# WB32F10x register map
File version: 1.2
CPU: CM3 r2p0, little endian, MPU, no FPU, 4 interrupt priority bits
Registers are 32-bit, read-write, reset 0x0 unless marked. A register's access mark holds for its fields unless they carry their own. Offsets are from the block's base; [hi:lo] are bit positions; {n}, {i} and the like mark numbered series; 'fields as' and 'values as' point back to an identical list.

## RTC — Real time clock controller
Base 0x40015800
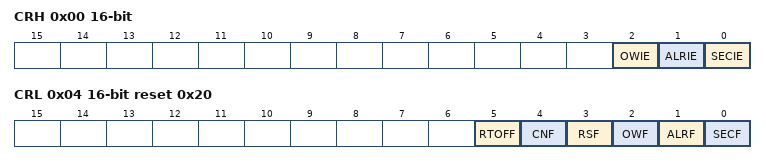
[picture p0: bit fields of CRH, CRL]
0x00 CRH 16-bit — Control high register
  [2] OWIE — Overflow interrupt enable
  [1] ALRIE — Alarm interrupt enable
  [0] SECIE — Second interrupt enable
0x04 CRL 16-bit reset 0x20 — Control low register
  [5] RTOFF — RTC operation turn-off flag
  [4] CNF — Configuration flag
  [3] RSF — Register synchronization flag
  [2] OWF — Overflow flag
  [1] ALRF — Alarm flag
  [0] SECF — Second flag
0x08 PRLH 16-bit wo — Prescaler high register
  [3:0] PRL — Prescaler high bits
0x0C PRLL 16-bit wo reset 0x8000 — Prescaler low register
  [15:0] PRL — Prescaler low bits
0x0C PRL ro (alternate view of PRLL) — Prescaler load register
  [31:0] PRL — Prescaler load
0x10 DIVH 16-bit ro — RTC clock divider high register
  [3:0] DIV — RTC clock divider high
0x14 DIVL 16-bit ro reset 0x8000 — RTC clock divider low register
  [15:0] DIV — RTC clock divider low
0x14 DIV ro (alternate view of DIVL) — RTC clock divider register
  [31:0] DIV — RTC clock divider
0x18 CNTH 16-bit — RTC counter high register
  [15:0] CNT — RTC counter high
0x1C CNTL 16-bit — RTC counter low register
  [15:0] CNT — RTC counter low
0x1C CNT ro (alternate view of CNTL) — RTC counter register
0x20 ALRH 16-bit wo reset 0xFFFF — RTC alarm high register
  [15:0] ALR — RTC alarm high
0x24 ALRL 16-bit wo reset 0xFFFF — RTC alarm low register
  [15:0] ALR — RTC alarm low
0x24 ALR ro reset 0xFFFFFFFF (alternate view of ALRL) — RTC alarm register

## WWDG — Window watchdog
Base 0x40009800
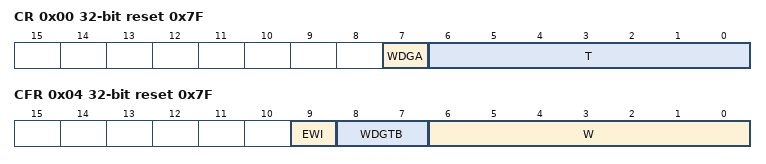
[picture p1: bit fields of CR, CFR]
0x00 CR reset 0x7F — Control register
  [7] WDGA — Window watchdog active bit
  [6:0] T — 7 bits counter
0x04 CFR reset 0x7F — Configuration register
  [9] EWI — Early wakeup interrupt
  [8:7] WDGTB — Window watchdog time base
  [6:0] W — 7 bits window value
0x08 SR — Status register
  [0] EWIF — Early wakeup interrupt flag

## IWDG — Independent watchdog
Base 0x40010800
0x00 KR wo — Key register
  [15:0] KEY — Key value
0x04 PR — Prescaler divider register
  [2:0] PR — Prescaler divider
0x08 RLR reset 0xFFF — Reload register
  [0] RL — Watchdog counter reload value
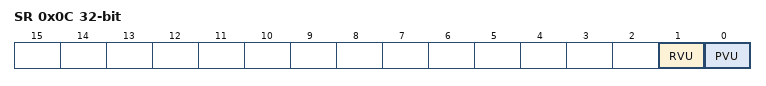
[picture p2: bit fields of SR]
0x0C SR ro — Status register
  [1] RVU — Watchdog counter reload value update
  [0] PVU — Watchdog prescaler value update

## DBGMCU — Debug MCU
Base 0xE0042000
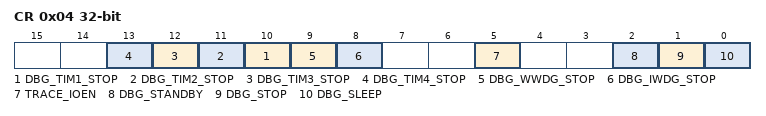
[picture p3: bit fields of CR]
0x04 CR — Control register
  [n+9] DBG_TIM{n}_STOP (n=1..4) — Timer {n} stop working in debug mode
  [9] DBG_WWDG_STOP — Window watchdog stop working in debug mode
  [8] DBG_IWDG_STOP — Independent watchdog stop working in debug mode
  [5] TRACE_IOEN — Trace IO enable
  [2] DBG_STANDBY — Debug standby mode
  [1] DBG_STOP — Debug stop mode
  [0] DBG_SLEEP — Debug sleep mode

## SFM — Special function macro
Base 0x40014C00
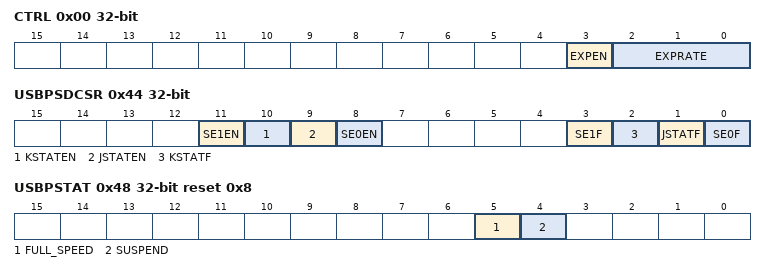
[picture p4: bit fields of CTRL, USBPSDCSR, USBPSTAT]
0x00 CTRL — Control register
  [3] EXPEN — Expand enable
  [2:0] EXPRATE — Expand rate
0x04 DATA
{0x8+4i} DOUTR{i} ro (i=0..7) — Data output register {i}
  [31:0] DOUT — Data output
0x44 USBPSDCSR — Usb port state detect control/status register
  [11] SE1EN — USB SE1 state detect enable
  [10] KSTATEN — USB K state detect enable
  [9] JSTATEN — USB J state detect enable
  [8] SE0EN — USB SE0 state detect enable
  [3] SE1F — USB switches to SE1 state from port state flag
  [2] KSTATF — USB switches to K state from port state flag
  [1] JSTATF — USB switches to J state from port state flag
  [0] SE0F — USB switches to SE0 state from port state flag
0x48 USBPSTAT ro reset 0x8 — Usb port state register
  [5] FULL_SPEED — Full speed state
  [4] SUSPEND — Suspend state

## CACHE — Cache controller
Base 0x40015400
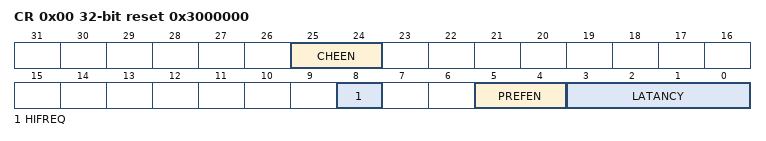
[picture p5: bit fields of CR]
0x00 CR reset 0x3000000 — Control register
  [25:24] CHEEN — Cache enable
  [8] HIFREQ — High frequency access assistance
  [5:4] PREFEN — Prefetch instruction enable
  [3:0] LATANCY — Flash memory access waiting latency

## FMC — Flash memory controller
Base 0x40017800
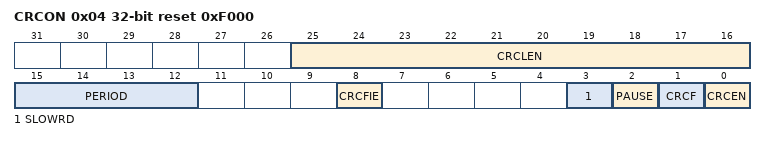
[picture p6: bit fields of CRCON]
0x04 CRCON reset 0xF000 — CRC control register
  [25:16] CRCLEN — CRC calculation length
  [15:12] PERIOD — Period to read flash while CRC calculation
  [8] CRCFIE — CRC calculation complete interrupt enable
  [3] SLOWRD — Control CRC calculation interval period
  [2] PAUSE — CRC pause
  [1] CRCF — CRC calculation complete flag
  [0] CRCEN — CRC enable
0x10 ADDR — Address register
  [31:0] Data — Adress data
0x1C DATA1
  [31:0] Data — Address data
{0x100+4i} BUF{i} wo (i=0..63) — Buffer {i} register
  [31:0] Data — Buffer data

## ISO — ISO7816 controller
Base 0x40016000
0x00 TXBUF wo — Transmit buffer register
  [7:0] WDATA — Transmit Date buffer
0x04 RXBUF ro — Receive buffer register
  [7:0] RDATA — Receive Date buffer
0x08 TXDONE ro — Transmit done register
  [0] TXDONE — Transmit done
0x0C RXDONE ro — Receive done register
  [0] RXDONE — Receive done buffer
0x10 STARTDET ro — Start detect register
  [0] START — Start bit detected
0x14 CLRTXDONE ro — Clear transmit done register
  [0] CLRTXDONE — Clear transmit done
0x18 CLRRXDONE ro — Clear receive done register
  [0] CLRRXDONE — Clear receive done
0x1C CLRSTART ro — Clear start bit flag register
  [0] CLRSTART — Clear start bit flag
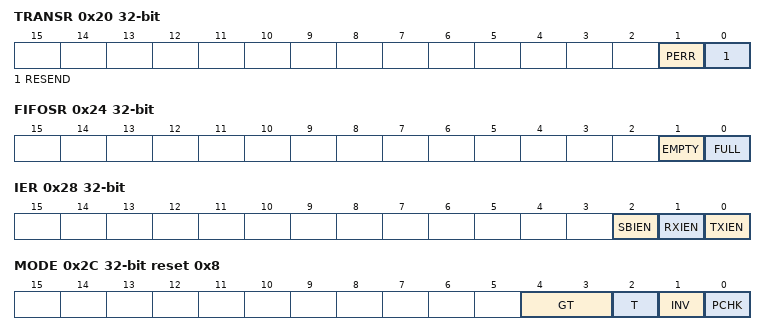
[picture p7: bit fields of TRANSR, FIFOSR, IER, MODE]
0x20 TRANSR ro — Transmit status register
  [1] PERR — Parity check error flag
  [0] RESEND — Resend flag
0x24 FIFOSR ro — FIFO status register
  [1] EMPTY — Buffer is empty
  [0] FULL — Buffer is full
0x28 IER — Interrupt mask control register
  [2] SBIEN — Start bit interrupt enable
  [1] RXIEN — Receive interrupt enable
  [0] TXIEN — Transmit interrupt enable
0x2C MODE reset 0x8
  [4:3] GT — Guard time
  [2] T — T mode
  [1] INV — Inverse mode
  [0] PCHK — Parity check control
0x30 ETU — ETU configuration register
  [10:0] CYCLE — ETU cycle
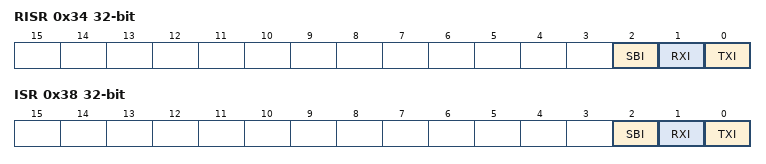
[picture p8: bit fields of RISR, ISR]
0x34 RISR ro — Raw interrupt status register
  [2] SBI — Start bit interrupt
  [1] RXI — Receive interrupt
  [0] TXI — Transmit interrupt
0x38 ISR ro — Interrupt status register
  fields as RISR
